# ipro7 register map
Vendor: intelpro; Series: BTBLE
CPU: ipro7, little endian
Registers are 32-bit, read-write, reset 0x0 unless marked. A register's access mark holds for its fields unless they carry their own. Offsets are from the block's base; [hi:lo] are bit positions; {n}, {i} and the like mark numbered series.

## SEC_DBG
Base 0x30005000
0x00 sd_chip_id_low reset not defined
  [31:0] sd_chip_id_low ro
0x04 sd_chip_id_high reset not defined
  [31:0] sd_chip_id_high ro
0x08 sd_dbg_pwd_low
0x0C sd_dbg_pwd_high
0x10 sd_dbg_pwd2_low
0x14 sd_dbg_pwd2_high
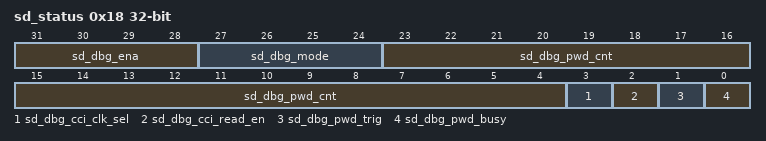
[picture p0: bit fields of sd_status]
0x18 sd_status (reset mask 0xE)
  [31:28] sd_dbg_ena ro, [27:24] sd_dbg_mode ro, [23:4] sd_dbg_pwd_cnt ro, [3] sd_dbg_cci_clk_sel, [2] sd_dbg_cci_read_en, [1] sd_dbg_pwd_trig, [0] sd_dbg_pwd_busy ro
0x1C sd_dbg_reserved reset 0xFFFF

## EF_D0
Base 0x30008000
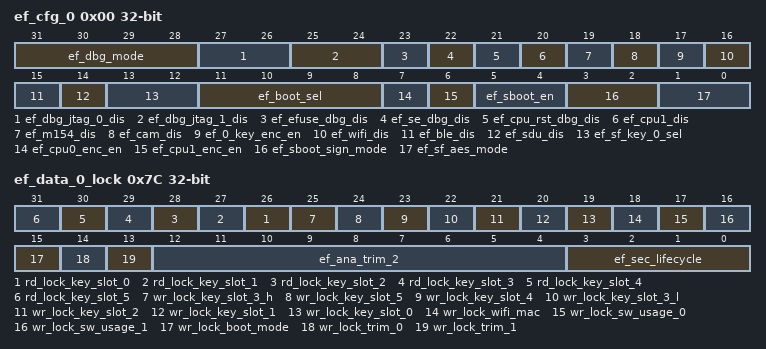
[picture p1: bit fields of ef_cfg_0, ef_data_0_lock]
0x00 ef_cfg_0
  [31:28] ef_dbg_mode — 4'b0000:open mode 4'b0001:password mode 4'b0010:password mode 4'b0011:password mode others:close mode
  [27:26] ef_dbg_jtag_0_dis — 2'b00:enable JTAG port 0 others:disable JTAG port 0
  [25:24] ef_dbg_jtag_1_dis — 2'b00:enable JTAG port 1 others:disable JTAG port 1
  [23] ef_efuse_dbg_dis — 2'b00:enable eFuse manual mode others:disable eFuse manual mode
  [22] ef_se_dbg_dis — 2'b00:unprotected Others:disable secure engine debug mode
  [21] ef_cpu_rst_dbg_dis — 2'b00:unprotected Others:disable cpu reset debug mode
  [20] ef_cpu1_dis — 1:disable cpu1
  [19] ef_m154_dis — 1:disable m154
  [18] ef_cam_dis — 1:disable camera
  [17] ef_0_key_enc_en — 2'b00:disable efuse 0 key slot and debug port password encryption Others:enable efuse 0 key slot and debug port password encryption
  [16] ef_wifi_dis — 1:disable wifi
  [15] ef_ble_dis — 1:disable ble
  [14] ef_sdu_dis — 1:disable sdu
  [13:12] ef_sf_key_0_sel — 2'b00:select key slot 2 2'b01:select key slot 3 2'b10:select key slot 4 2'b11:select key slot 2
  [11:8] ef_boot_sel — [3] 1:APP on E21 [2] 1:APP on M0 [1] 1:boot from E21 [0] 1:boot from M0
  [7] ef_cpu0_enc_en — 1:encrypt cpu0
  [6] ef_cpu1_enc_en — 1:encrypt cpu1
  [5:4] ef_sboot_en — 4'b0000:secure boot disable others:secure boot enable
  [3:2] ef_sboot_sign_mode — 2'b00:unsign 2'b01:sign CPU 0 only 2'b10:sign CPU 1 only 2'b11:sign CPU 0 and CPU 1
  [1:0] ef_sf_aes_mode — 2'b00:plaintext 2'b01:AES-128 2'b10:AES-192 2'b11:AES-256
0x04 ef_sw_usage_0
0x08 ef_sw_usage_1
0x0C ef_ana_trim_0
0x10 ef_ana_trim_1
0x14 ef_wifi_mac_low
  [31:0] ef_wifi_mac_low — MAC address[31:0]
0x18 ef_wifi_mac_high
  [31:0] ef_wifi_mac_high — MAC address[63:32]
{0x1C+0x10*i} ef_key_slot_{i}_w0 (i=0..4)
  [31:0] ef_key_slot_{i}_w0 — AES key slot {i}
{0x20+0x10*i} ef_key_slot_{i}_w1 (i=0..4)
  [31:0] ef_key_slot_{i}_w1 — AES key slot {i}
{0x24+0x10*i} ef_key_slot_{i}_w2 (i=0..4)
  [31:0] ef_key_slot_{i}_w2 — AES key slot {i}
{0x28+0x10*i} ef_key_slot_{i}_w3 (i=0..4)
  [31:0] ef_key_slot_{i}_w3 — AES key slot {i}
{0x6C+4i} ef_key_slot_5_w{i} (i=0..3)
  [31:0] ef_key_slot_5_w{i} — AES key slot 5 or debug port password[{32i+31}:{32i}] (ef_dbg_mode = password mode)
0x7C ef_data_0_lock
  [n+26] rd_lock_key_slot_{n} (n=0..5)
  [25] wr_lock_key_slot_3_h
  [24] wr_lock_key_slot_5
  [23] wr_lock_key_slot_4
  [22] wr_lock_key_slot_3_l
  [21] wr_lock_key_slot_2
  [20] wr_lock_key_slot_1
  [19] wr_lock_key_slot_0
  [18] wr_lock_wifi_mac
  [17] wr_lock_sw_usage_0
  [16] wr_lock_sw_usage_1
  [15] wr_lock_boot_mode
  [14] wr_lock_trim_0
  [13] wr_lock_trim_1
  [12:4] ef_ana_trim_2
  [3:0] ef_sec_lifecycle — 4'b0000:initial state 4'b0001:provisioning state 4'b0011:reserved state 4'b0111:secure state: enable sboot, disable debug signals from secure module 4'b1111:decommissioned state: zerorize all keys, disable all debug ports

## EF_D1
Base 0x30008000
{0x20+0x10*i} reg_key_slot_{i}_w0 (i=6..9)
  [31:0] reg_key_slot_{i}_w0 — AES key slot {i}
{0x24+0x10*i} reg_key_slot_{i}_w1 (i=6..9)
  [31:0] reg_key_slot_{i}_w1 — AES key slot {i}
{0x28+0x10*i} reg_key_slot_{i}_w2 (i=6..9)
  [31:0] reg_key_slot_{i}_w2 — AES key slot {i}
{0x2C+0x10*i} reg_key_slot_{i}_w3 (i=6..9)
  [31:0] reg_key_slot_{i}_w3 — AES key slot {i}
{0xC0+4i} reg_key_slot_10_w{i} (i=0..3)
{0xD0+4i} reg_key_slot_11_w{i} (i=0..3)
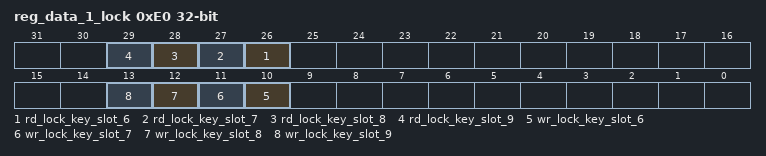
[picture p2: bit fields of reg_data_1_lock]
0xE0 reg_data_1_lock
  [n+20] rd_lock_key_slot_{n} (n=6..9), [n+4] wr_lock_key_slot_{n} (n=6..9)
